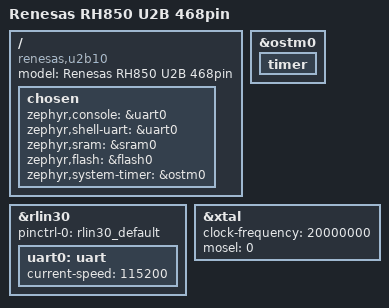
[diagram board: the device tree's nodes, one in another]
/*
 * Copyright (c) 2026 Renesas Electronics Corporation
 * SPDX-License-Identifier: Apache-2.0
 */

/dts-v1/;

#include <rh850/renesas/u2b/u2b10/r7f70254xafabg-c.dtsi>
#include <dt-bindings/gpio/gpio.h>

#include "pb_rh850u2b_468pin-pinctrl.dtsi"

/ {
	model = "Renesas RH850 U2B 468pin";
	compatible = "renesas,u2b10", "renesas,u2b";

	chosen {
		zephyr,console = &uart0;
		zephyr,shell-uart = &uart0;
		zephyr,sram = &sram0;
		zephyr,flash = &flash0;
		zephyr,system-timer = &ostm0;
	};
};

&ostm0 {
	status = "okay";

	timer {
		status = "okay";
	};
};

&rlin30 {
	pinctrl-0 = <&rlin30_default>;
	pinctrl-names = "default";
	status = "okay";

	uart0: uart {
		current-speed = <115200>;
		status = "okay";
	};
};

&xtal {
	clock-frequency = <20000000>;
	mosel = <0>;
	#clock-cells = <0>;
	status = "okay";
};


